# MPU_8_MPU_8_40120000h register map
Vendor: Texas Instruments
Peripheral module from a debugger description file (folder AM263P).
Registers are 32-bit, read-write, reset 0x0 unless marked. A register's access mark holds for its fields unless they carry their own. Offsets are as the file gives them; lines under a group give offsets from that group; [hi:lo] are bit positions; {n}, {i} and the like mark numbered series; 'fields as' and 'values as' point back to an identical list; <NAME> marks a mode.

## MPU_8
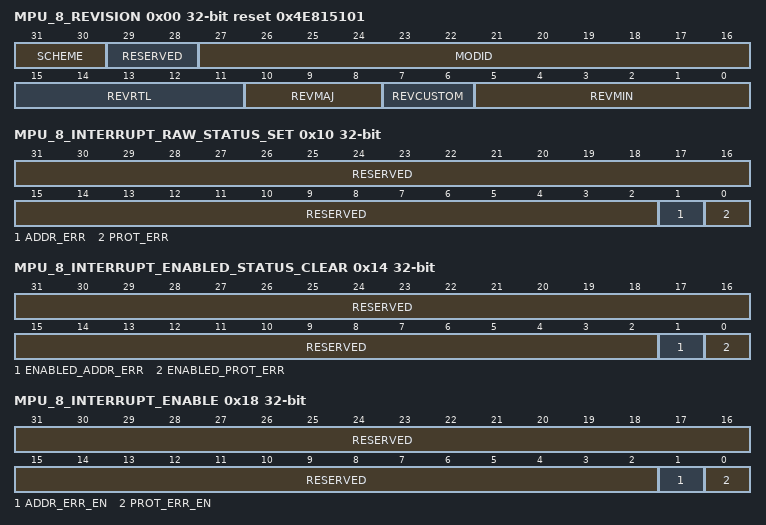
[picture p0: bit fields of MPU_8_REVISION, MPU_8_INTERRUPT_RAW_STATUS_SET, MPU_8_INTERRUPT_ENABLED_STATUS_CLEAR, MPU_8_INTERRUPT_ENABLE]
0x00 MPU_8_REVISION ro reset 0x4E815101 — Revision.
  [31:30] SCHEME
  [29:28] RESERVED — Always read a s0. Writes have no affect.
  [27:16] MODID — Module ID field.
  [15:11] REVRTL — RTL revision.Will vary depending on release.
  [10:8] REVMAJ — Major revision.
  [7:6] REVCUSTOM — Custom revision.
  [5:0] REVMIN — Minor revision.
0x10 MPU_8_INTERRUPT_RAW_STATUS_SET access not given — Interrupt_Raw_Status_Set.
  [31:2] RESERVED ro — Always read as 0.
  [1] ADDR_ERR — Addressing violation error. Raw status is read.Write a 1 to set the status. Writing a 0 has no effect. (access R/W1TS)
  [0] PROT_ERR — Protection violation error. Raw status is read. Write a 1 to set the status. Writing a 0 has no effect. (access R/W1TS)
0x14 MPU_8_INTERRUPT_ENABLED_STATUS_CLEAR access not given — Interrupt_Enabled_Status_Clear.
  [31:2] RESERVED ro — Always read as 0.
  [1] ENABLED_ADDR_ERR — Addressing violation error. Enabled status is read.Write a 1 to clear the status. Writing a 0 has no effect. (access R/W0TC)
  [0] ENABLED_PROT_ERR — Protection violation error. Enabled status is read. Write a 1 to clear the status. Writing a 0 has no effect. (access R/W0TC)
0x18 MPU_8_INTERRUPT_ENABLE access not given — Interrupt_Enable.
  [31:2] RESERVED ro — Always read as 0.
  [1] ADDR_ERR_EN — Addressing violation error enable. Write a 1 to set the enable. Writing a 0 has no effect. (access R/W1TS)
  [0] PROT_ERR_EN — Protection violation error enable. Write a 1 to set the enable. Writing a 0 has no effect. (access R/W1TS)
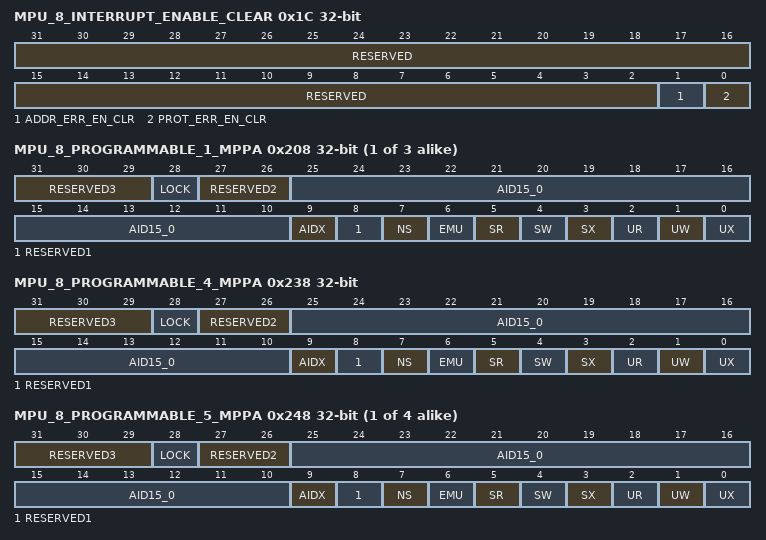
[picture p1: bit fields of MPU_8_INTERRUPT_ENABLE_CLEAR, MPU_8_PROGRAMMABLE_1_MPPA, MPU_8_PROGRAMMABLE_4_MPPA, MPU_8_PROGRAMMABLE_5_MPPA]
0x1C MPU_8_INTERRUPT_ENABLE_CLEAR access not given — Interrupt_Enable_Clear.
  [31:2] RESERVED ro — Always read as 0.
  [1] ADDR_ERR_EN_CLR — Addressing violation error enable. Write a 1 to clear the enable. Writing a 0 has no effect. (access R/W0TC)
  [0] PROT_ERR_EN_CLR — Protection violation error enable. Write a 1 to clear the enable. Writing a 0 has no effect. (access R/W0TC)
{0x1F0+0x10*i} MPU_8_PROGRAMMABLE_{i}_START_ADDRESS (i=1..8) — Programmable_{i}_Start_Address.
  [31:0] START_ADDR — Start address for range N. Defaults to input signal value.
{0x1F4+0x10*i} MPU_8_PROGRAMMABLE_{i}_END_ADDRESS (i=1..8) — Programmable_{i}_End_Address.
  [31:0] END_ADDR — End address for range N. Defaults to input signal value.
{0x1F8+0x10*i} MPU_8_PROGRAMMABLE_{i}_MPPA access per field (i=1..3) — Programmable_{i}_MPPA.
  [31:29] RESERVED3 ro — Always read as 0
  [28] LOCK rw — this field is used for locking the corresponding MPU region configurations. Write 1 to lock the configurations along with the lock bit.Writing 1 is alllowed once per boot. Lock bit will clear on reset only.Once locked SW can not modify the MPU configurations along with lock bit.
  [27:26] RESERVED2 ro — Always read as 0.
  [25:10] AID15_0 rw — AIDs checked for this region. Defaults to input value.0 = AID is not checked for these permissions.1 = AID is checked for these permissions.
  [9] AIDX rw — Additional AIDs checked. Defaults to input value.
  [8] RESERVED1 ro — Always read as 0.
  [7] NS rw — Non-secure permission. Defaults to input value.
  [6] EMU rw — Debug permission. Defaults to input value.
  [5] SR rw — Supervisor read permission. Defaults to input value.
  [4] SW rw — Supervisor write permission. Defaults to input value.
  [3] SX rw — Supervisor executable permission. Defaults to input value.
  [2] UR rw — User read permission. Defaults to input value.
  [1] UW rw — User write permission. Defaults to input value.
  [0] UX rw — User executable permission. Defaults to input value.
0x238 MPU_8_PROGRAMMABLE_4_MPPA access per field — Programmable_4_MPPA.
  [31:29] RESERVED3 ro — Always read as 0
  [28] LOCK rw — this field is used for locking the corresponding MPU region configurations. Write 1 to lock the configurations along with the lock bit.Writing 1 is alllowed once per boot. Lock bit will reset clear on reset only.Once locked SW can not modify the MPU configurations along with lock bit.
  [27:26] RESERVED2 ro — Always read as 0.
  [25:10] AID15_0 rw — AIDs checked for this region. Defaults to input value.0 = AID is not checked for these permissions.1 = AID is checked for these permissions.
  [9] AIDX rw — Additional AIDs checked. Defaults to input value.
  [8] RESERVED1 ro — Always read as 0.
  [7] NS rw — Non-secure permission. Defaults to input value.
  [6] EMU rw — Debug permission. Defaults to input value.
  [5] SR rw — Supervisor read permission. Defaults to input value.
  [4] SW rw — Supervisor write permission. Defaults to input value.
  [3] SX rw — Supervisor executable permission. Defaults to input value.
  [2] UR rw — User read permission. Defaults to input value.
  [1] UW rw — User write permission. Defaults to input value.
  [0] UX rw — User executable permission. Defaults to input value.
{0x1F8+0x10*i} MPU_8_PROGRAMMABLE_{i}_MPPA access per field (i=5..8) — Programmable_{i}_MPPA.
  fields as MPU_8_PROGRAMMABLE_1_MPPA
0x300 MPU_8_FAULT_ADDRESS ro — Fault_Address.
  [31:0] FAULT_ADDR — Fault_address.
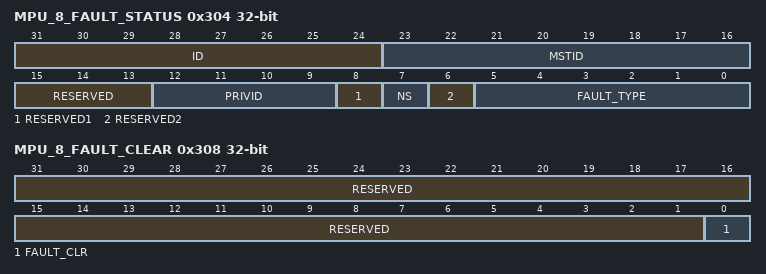
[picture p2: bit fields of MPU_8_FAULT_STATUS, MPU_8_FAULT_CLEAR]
0x304 MPU_8_FAULT_STATUS ro — Fault_Status.
  [31:24] ID — Transfer ID
  [23:16] MSTID — Master ID.
  [15:13] RESERVED — Always read as 0.
  [12:9] PRIVID — Privilege ID.
  [8] RESERVED1 — Always read as 0.
  [7] NS — Non-secure access.
  [6] RESERVED2 — Always read as 0.
  [5:0] FAULT_TYPE — Fault_type.100000 = supervisor read fault010000 = supervisor write fault001000 = supervisor execute fault000100 = user read fault000010 = user write fault000001 = user execute fault111111 = relaxed cache linefill fault010010 = relaxed cache writeback fault000000 = no fault
0x308 MPU_8_FAULT_CLEAR access per field — Fault_Clear.
  [31:1] RESERVED ro — Always read as 0.
  [0] FAULT_CLR wo — Fault_clear. Writing a 1 clears the current fault. Writing a0 has no effect.
